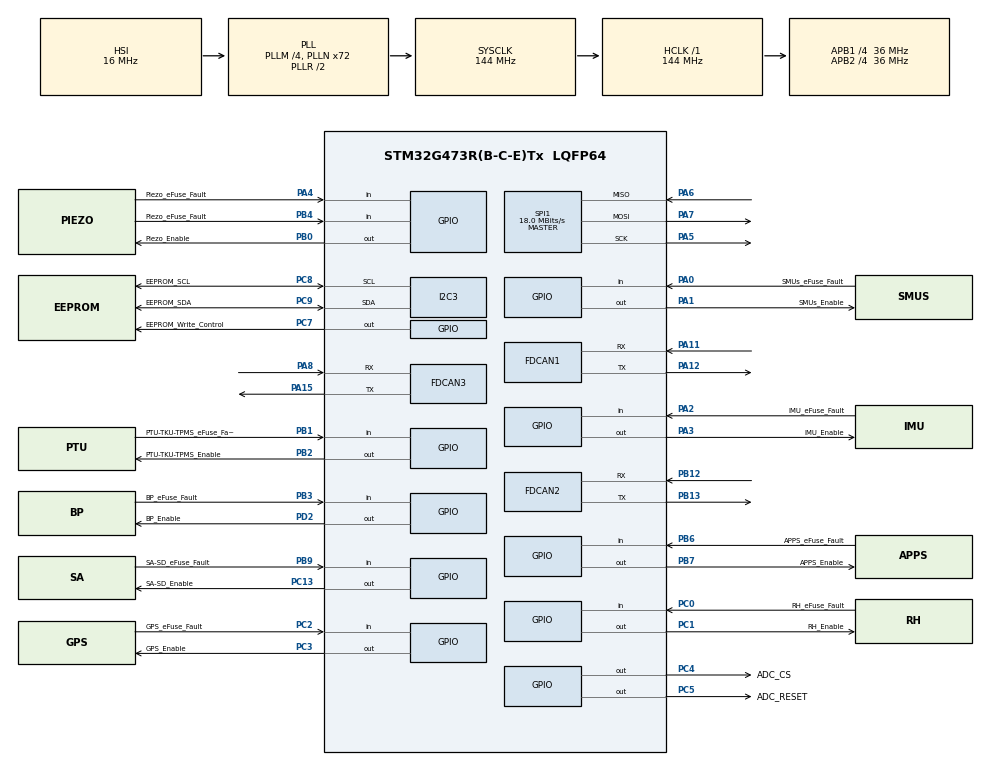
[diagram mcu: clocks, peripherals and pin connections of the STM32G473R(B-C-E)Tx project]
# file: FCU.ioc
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Dma.Request0=SPI1_RX
Dma.Request1=SPI1_TX
Dma.SPI1_RX.0.Direction=DMA_PERIPH_TO_MEMORY
Dma.SPI1_RX.0.EventEnable=DISABLE
Dma.SPI1_RX.0.Instance=DMA1_Channel1
Dma.SPI1_RX.0.MemDataAlignment=DMA_MDATAALIGN_BYTE
Dma.SPI1_RX.0.MemInc=DMA_MINC_ENABLE
Dma.SPI1_RX.0.Mode=DMA_NORMAL
Dma.SPI1_RX.0.PeriphDataAlignment=DMA_PDATAALIGN_BYTE
Dma.SPI1_RX.0.PeriphInc=DMA_PINC_DISABLE
Dma.SPI1_RX.0.Polarity=HAL_DMAMUX_REQ_GEN_RISING
Dma.SPI1_RX.0.Priority=DMA_PRIORITY_LOW
Dma.SPI1_RX.0.RequestNumber=1
Dma.SPI1_RX.0.SignalID=NONE
Dma.SPI1_RX.0.SyncEnable=DISABLE
Dma.SPI1_RX.0.SyncPolarity=HAL_DMAMUX_SYNC_NO_EVENT
Dma.SPI1_RX.0.SyncRequestNumber=1
Dma.SPI1_RX.0.SyncSignalID=NONE
Dma.SPI1_TX.1.Direction=DMA_MEMORY_TO_PERIPH
Dma.SPI1_TX.1.EventEnable=DISABLE
Dma.SPI1_TX.1.Instance=DMA1_Channel2
Dma.SPI1_TX.1.MemDataAlignment=DMA_MDATAALIGN_BYTE
Dma.SPI1_TX.1.MemInc=DMA_MINC_ENABLE
Dma.SPI1_TX.1.Mode=DMA_NORMAL
Dma.SPI1_TX.1.PeriphDataAlignment=DMA_PDATAALIGN_BYTE
Dma.SPI1_TX.1.PeriphInc=DMA_PINC_DISABLE
Dma.SPI1_TX.1.Polarity=HAL_DMAMUX_REQ_GEN_RISING
Dma.SPI1_TX.1.Priority=DMA_PRIORITY_LOW
Dma.SPI1_TX.1.RequestNumber=1
Dma.SPI1_TX.1.SignalID=NONE
Dma.SPI1_TX.1.SyncEnable=DISABLE
Dma.SPI1_TX.1.SyncPolarity=HAL_DMAMUX_SYNC_NO_EVENT
Dma.SPI1_TX.1.SyncRequestNumber=1
Dma.SPI1_TX.1.SyncSignalID=NONE
FDCAN1.CalculateBaudRateNominal=999999
FDCAN1.CalculateTimeBitNominal=1000
FDCAN1.CalculateTimeQuantumNominal=83.33333333333334
FDCAN1.FrameFormat=FDCAN_FRAME_FD_NO_BRS
FDCAN1.NominalPrescaler=3
FDCAN1.NominalTimeSeg1=8
FDCAN1.NominalTimeSeg2=3
FDCAN1.StdFiltersNbr=28
FDCAN2.CalculateBaudRateNominal=999999
FDCAN2.CalculateTimeBitNominal=1000
FDCAN2.CalculateTimeQuantumNominal=83.33333333333334
FDCAN2.NominalPrescaler=3
FDCAN2.NominalTimeSeg1=8
FDCAN2.NominalTimeSeg2=3
FDCAN2.StdFiltersNbr=28
FDCAN3.CalculateBaudRateNominal=999999
FDCAN3.CalculateTimeBitNominal=1000
FDCAN3.CalculateTimeQuantumNominal=83.33333333333334
FDCAN3.NominalPrescaler=3
FDCAN3.NominalTimeSeg1=8
FDCAN3.NominalTimeSeg2=3
FDCAN3.StdFiltersNbr=28
I2C3.Timing=0x00808CD2
Mcu.Family=STM32G4
Mcu.Name=STM32G473R(B-C-E)Tx
Mcu.Package=LQFP64
NVIC.DMA1_Channel1_IRQn=true\:6\:0\:true\:false\:true\:false\:true\:true
NVIC.DMA1_Channel2_IRQn=true\:6\:0\:true\:false\:true\:false\:true\:true
NVIC.PriorityGroup=NVIC_PRIORITYGROUP_4
PA0.GPIO_Label=SMUs_eFuse_Fault
PA0.Signal=GPIO_Input
PA1.GPIO_Label=SMUs_Enable
PA1.GPIO_ModeDefaultOutputPP=GPIO_MODE_OUTPUT_OD
PA1.GPIO_PuPd=GPIO_NOPULL
PA1.Signal=GPIO_Output
PA11.GPIO_Speed=GPIO_SPEED_FREQ_LOW
PA11.Mode=FDCAN_Activate
PA11.Signal=FDCAN1_RX
PA12.GPIO_PuPd=GPIO_NOPULL
PA12.Mode=FDCAN_Activate
PA12.Signal=FDCAN1_TX
PA13.Mode=Serial_Wire
PA13.Signal=SYS_JTMS-SWDIO
PA14.Mode=Serial_Wire
PA14.Signal=SYS_JTCK-SWCLK
PA15.Mode=FDCAN_Activate
PA15.Signal=FDCAN3_TX
PA2.GPIO_Label=IMU_eFuse_Fault
PA2.Signal=GPIO_Input
PA3.GPIO_Label=IMU_Enable
PA3.GPIO_ModeDefaultOutputPP=GPIO_MODE_OUTPUT_OD
PA3.GPIO_PuPd=GPIO_NOPULL
PA3.Signal=GPIO_Output
PA4.GPIO_Label=Piezo_eFuse_Fault
PA4.Signal=GPIO_Input
PA5.Mode=Full_Duplex_Master
PA5.Signal=SPI1_SCK
PA6.Mode=Full_Duplex_Master
PA6.Signal=SPI1_MISO
PA7.Mode=Full_Duplex_Master
PA7.Signal=SPI1_MOSI
PA8.Mode=FDCAN_Activate
PA8.Signal=FDCAN3_RX
PB0.GPIO_Label=Piezo_Enable
PB0.GPIO_ModeDefaultOutputPP=GPIO_MODE_OUTPUT_OD
PB0.GPIO_PuPd=GPIO_NOPULL
PB0.Signal=GPIO_Output
PB1.GPIO_Label=PTU-TKU-TPMS_eFuse_Fault
PB1.Signal=GPIO_Input
PB12.Mode=FDCAN_Activate
PB12.Signal=FDCAN2_RX
PB13.Mode=FDCAN_Activate
PB13.Signal=FDCAN2_TX
PB2.GPIO_Label=PTU-TKU-TPMS_Enable
PB2.GPIO_ModeDefaultOutputPP=GPIO_MODE_OUTPUT_OD
PB2.GPIO_PuPd=GPIO_NOPULL
PB2.PinState=GPIO_PIN_SET
PB2.Signal=GPIO_Output
PB3.GPIO_Label=BP_eFuse_Fault
PB3.Signal=GPIO_Input
PB4.GPIO_Label=Piezo_eFuse_Fault
PB4.Signal=GPIO_Input
PB6.GPIO_Label=APPS_eFuse_Fault
PB6.Signal=GPIO_Input
PB7.GPIO_Label=APPS_Enable
PB7.GPIO_ModeDefaultOutputPP=GPIO_MODE_OUTPUT_OD
PB7.GPIO_PuPd=GPIO_NOPULL
PB7.PinState=GPIO_PIN_SET
PB7.Signal=GPIO_Output
PB9.GPIO_Label=SA-SD_eFuse_Fault
PB9.Signal=GPIO_Input
PC0.GPIO_Label=RH_eFuse_Fault
PC0.Signal=GPIO_Input
PC1.GPIO_Label=RH_Enable
PC1.GPIO_ModeDefaultOutputPP=GPIO_MODE_OUTPUT_OD
PC1.GPIO_PuPd=GPIO_NOPULL
PC1.Signal=GPIO_Output
PC13.GPIO_Label=SA-SD_Enable
PC13.GPIO_ModeDefaultOutputPP=GPIO_MODE_OUTPUT_OD
PC13.GPIO_PuPd=GPIO_NOPULL
PC13.Signal=GPIO_Output
PC2.GPIO_Label=GPS_eFuse_Fault
PC2.Signal=GPIO_Input
PC3.GPIO_Label=GPS_Enable
PC3.GPIO_ModeDefaultOutputPP=GPIO_MODE_OUTPUT_OD
PC3.GPIO_PuPd=GPIO_NOPULL
PC3.Signal=GPIO_Output
PC4.GPIO_Label=ADC_CS
PC4.PinState=GPIO_PIN_SET
PC4.Signal=GPIO_Output
PC5.GPIO_Label=ADC_RESET
PC5.PinState=GPIO_PIN_SET
PC5.Signal=GPIO_Output
PC7.GPIO_Label=EEPROM_Write_Control
PC7.Signal=GPIO_Output
PC8.GPIO_Label=EEPROM_SCL
PC8.Mode=I2C
PC8.Signal=I2C3_SCL
PC9.GPIO_Label=EEPROM_SDA
PC9.Mode=I2C
PC9.Signal=I2C3_SDA
PD2.GPIO_Label=BP_Enable
PD2.Signal=GPIO_Output
ProjectManager.HeapSize=0x200
ProjectManager.StackSize=0x400
ProjectManager.TargetToolchain=MDK-ARM V5.32
RCC.ADC12Freq_Value=144000000
RCC.ADC345Freq_Value=144000000
RCC.AHBFreq_Value=144000000
RCC.APB1CLKDivider=RCC_HCLK_DIV4
RCC.APB1Freq_Value=36000000
RCC.APB1TimFreq_Value=72000000
RCC.APB2CLKDivider=RCC_HCLK_DIV4
RCC.APB2Freq_Value=36000000
RCC.APB2TimFreq_Value=72000000
RCC.CortexFreq_Value=144000000
RCC.EXTERNAL_CLOCK_VALUE=12288000
RCC.HCLKFreq_Value=144000000
RCC.HSE_VALUE=8000000
RCC.HSI48_VALUE=48000000
RCC.HSI_VALUE=16000000
RCC.LSE_VALUE=32768
RCC.PLLM=RCC_PLLM_DIV4
RCC.PLLN=72
RCC.SYSCLKFreq_VALUE=144000000
RCC.SYSCLKSource=RCC_SYSCLKSOURCE_PLLCLK
RCC.USBFreq_Value=144000000
RCC.VCOOutputFreq_Value=288000000
SPI1.BaudRatePrescaler=SPI_BAUDRATEPRESCALER_2
SPI1.CalculateBaudRate=18.0 MBits/s
SPI1.DataSize=SPI_DATASIZE_8BIT
SPI1.Direction=SPI_DIRECTION_2LINES
SPI1.Mode=SPI_MODE_MASTER
SPI1.VirtualType=VM_MASTER
VP_SYS_VS_DBSignals.Mode=DisableDeadBatterySignals
board=custom

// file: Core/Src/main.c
/* USER CODE BEGIN Header */
/**
  ******************************************************************************
  * @file           : main.c
  * @brief          : Main program body
  ******************************************************************************
  * @attention
  *
  * Copyright (c) 2024 STMicroelectronics.
  * All rights reserved.
  *
  * This software is licensed under terms that can be found in the LICENSE file
  * in the root directory of this software component.
  * If no LICENSE file comes with this software, it is provided AS-IS.
  *
  ******************************************************************************
  */
/* USER CODE END Header */
#include "main.h"

/* USER CODE BEGIN PM */
#define main initHAL
/* USER CODE END PM */

FDCAN_HandleTypeDef hfdcan1;
FDCAN_HandleTypeDef hfdcan2;
FDCAN_HandleTypeDef hfdcan3;

I2C_HandleTypeDef hi2c3;

SPI_HandleTypeDef hspi1;
DMA_HandleTypeDef hdma_spi1_rx;
DMA_HandleTypeDef hdma_spi1_tx;

void SystemClock_Config(void);
static void MX_GPIO_Init(void);
static void MX_DMA_Init(void);
static void MX_I2C3_Init(void);
static void MX_SPI1_Init(void);
static void MX_FDCAN2_Init(void);
static void MX_FDCAN1_Init(void);
static void MX_FDCAN3_Init(void);

int main(void)
{

  /* MCU Configuration--------------------------------------------------------*/

  /* Reset of all peripherals, Initializes the Flash interface and the Systick. */
  HAL_Init();

  /* Configure the system clock */
  SystemClock_Config();

  /* Initialize all configured peripherals */
  MX_GPIO_Init();
  MX_DMA_Init();
  MX_I2C3_Init();
  MX_SPI1_Init();
  MX_FDCAN2_Init();
  MX_FDCAN1_Init();
  MX_FDCAN3_Init();

  /* Infinite loop */
  while (1)
  {

    /* USER CODE BEGIN 3 */
    break;
  }
  /* USER CODE END 3 */
}

void SystemClock_Config(void)
{
  RCC_OscInitTypeDef RCC_OscInitStruct = {0};
  RCC_ClkInitTypeDef RCC_ClkInitStruct = {0};

  /** Configure the main internal regulator output voltage
  */
  HAL_PWREx_ControlVoltageScaling(PWR_REGULATOR_VOLTAGE_SCALE1);

  /** Initializes the RCC Oscillators according to the specified parameters
  * in the RCC_OscInitTypeDef structure.
  */
  RCC_OscInitStruct.OscillatorType = RCC_OSCILLATORTYPE_HSI;
  RCC_OscInitStruct.HSIState = RCC_HSI_ON;
  RCC_OscInitStruct.HSICalibrationValue = RCC_HSICALIBRATION_DEFAULT;
  RCC_OscInitStruct.PLL.PLLState = RCC_PLL_ON;
  RCC_OscInitStruct.PLL.PLLSource = RCC_PLLSOURCE_HSI;
  RCC_OscInitStruct.PLL.PLLM = RCC_PLLM_DIV4;
  RCC_OscInitStruct.PLL.PLLN = 72;
  RCC_OscInitStruct.PLL.PLLP = RCC_PLLP_DIV2;
  RCC_OscInitStruct.PLL.PLLQ = RCC_PLLQ_DIV2;
  RCC_OscInitStruct.PLL.PLLR = RCC_PLLR_DIV2;
  if (HAL_RCC_OscConfig(&RCC_OscInitStruct) != HAL_OK)
  {
    Error_Handler();
  }

  /** Initializes the CPU, AHB and APB buses clocks
  */
  RCC_ClkInitStruct.ClockType = RCC_CLOCKTYPE_HCLK|RCC_CLOCKTYPE_SYSCLK
                              |RCC_CLOCKTYPE_PCLK1|RCC_CLOCKTYPE_PCLK2;
  RCC_ClkInitStruct.SYSCLKSource = RCC_SYSCLKSOURCE_PLLCLK;
  RCC_ClkInitStruct.AHBCLKDivider = RCC_SYSCLK_DIV1;
  RCC_ClkInitStruct.APB1CLKDivider = RCC_HCLK_DIV4;
  RCC_ClkInitStruct.APB2CLKDivider = RCC_HCLK_DIV4;

  if (HAL_RCC_ClockConfig(&RCC_ClkInitStruct, FLASH_LATENCY_4) != HAL_OK)
  {
    Error_Handler();
  }
}

static void MX_FDCAN1_Init(void)
{

  hfdcan1.Instance = FDCAN1;
  hfdcan1.Init.ClockDivider = FDCAN_CLOCK_DIV1;
  hfdcan1.Init.FrameFormat = FDCAN_FRAME_FD_NO_BRS;
  hfdcan1.Init.Mode = FDCAN_MODE_NORMAL;
  hfdcan1.Init.AutoRetransmission = DISABLE;
  hfdcan1.Init.TransmitPause = DISABLE;
  hfdcan1.Init.ProtocolException = DISABLE;
  hfdcan1.Init.NominalPrescaler = 3;
  hfdcan1.Init.NominalSyncJumpWidth = 1;
  hfdcan1.Init.NominalTimeSeg1 = 8;
  hfdcan1.Init.NominalTimeSeg2 = 3;
  hfdcan1.Init.DataPrescaler = 1;
  hfdcan1.Init.DataSyncJumpWidth = 1;
  hfdcan1.Init.DataTimeSeg1 = 1;
  hfdcan1.Init.DataTimeSeg2 = 1;
  hfdcan1.Init.StdFiltersNbr = 28;
  hfdcan1.Init.ExtFiltersNbr = 0;
  hfdcan1.Init.TxFifoQueueMode = FDCAN_TX_FIFO_OPERATION;
  if (HAL_FDCAN_Init(&hfdcan1) != HAL_OK)
  {
    Error_Handler();
  }

}

static void MX_FDCAN2_Init(void)
{

  hfdcan2.Instance = FDCAN2;
  hfdcan2.Init.ClockDivider = FDCAN_CLOCK_DIV1;
  hfdcan2.Init.FrameFormat = FDCAN_FRAME_CLASSIC;
  hfdcan2.Init.Mode = FDCAN_MODE_NORMAL;
  hfdcan2.Init.AutoRetransmission = DISABLE;
  hfdcan2.Init.TransmitPause = DISABLE;
  hfdcan2.Init.ProtocolException = DISABLE;
  hfdcan2.Init.NominalPrescaler = 3;
  hfdcan2.Init.NominalSyncJumpWidth = 1;
  hfdcan2.Init.NominalTimeSeg1 = 8;
  hfdcan2.Init.NominalTimeSeg2 = 3;
  hfdcan2.Init.DataPrescaler = 1;
  hfdcan2.Init.DataSyncJumpWidth = 1;
  hfdcan2.Init.DataTimeSeg1 = 1;
  hfdcan2.Init.DataTimeSeg2 = 1;
  hfdcan2.Init.StdFiltersNbr = 28;
  hfdcan2.Init.ExtFiltersNbr = 0;
  hfdcan2.Init.TxFifoQueueMode = FDCAN_TX_FIFO_OPERATION;
  if (HAL_FDCAN_Init(&hfdcan2) != HAL_OK)
  {
    Error_Handler();
  }

}

static void MX_FDCAN3_Init(void)
{

  hfdcan3.Instance = FDCAN3;
  hfdcan3.Init.ClockDivider = FDCAN_CLOCK_DIV1;
  hfdcan3.Init.FrameFormat = FDCAN_FRAME_CLASSIC;
  hfdcan3.Init.Mode = FDCAN_MODE_NORMAL;
  hfdcan3.Init.AutoRetransmission = DISABLE;
  hfdcan3.Init.TransmitPause = DISABLE;
  hfdcan3.Init.ProtocolException = DISABLE;
  hfdcan3.Init.NominalPrescaler = 3;
  hfdcan3.Init.NominalSyncJumpWidth = 1;
  hfdcan3.Init.NominalTimeSeg1 = 8;
  hfdcan3.Init.NominalTimeSeg2 = 3;
  hfdcan3.Init.DataPrescaler = 1;
  hfdcan3.Init.DataSyncJumpWidth = 1;
  hfdcan3.Init.DataTimeSeg1 = 1;
  hfdcan3.Init.DataTimeSeg2 = 1;
  hfdcan3.Init.StdFiltersNbr = 28;
  hfdcan3.Init.ExtFiltersNbr = 0;
  hfdcan3.Init.TxFifoQueueMode = FDCAN_TX_FIFO_OPERATION;
  if (HAL_FDCAN_Init(&hfdcan3) != HAL_OK)
  {
    Error_Handler();
  }

}

static void MX_I2C3_Init(void)
{

  hi2c3.Instance = I2C3;
  hi2c3.Init.Timing = 0x00808CD2;
  hi2c3.Init.OwnAddress1 = 0;
  hi2c3.Init.AddressingMode = I2C_ADDRESSINGMODE_7BIT;
  hi2c3.Init.DualAddressMode = I2C_DUALADDRESS_DISABLE;
  hi2c3.Init.OwnAddress2 = 0;
  hi2c3.Init.OwnAddress2Masks = I2C_OA2_NOMASK;
  hi2c3.Init.GeneralCallMode = I2C_GENERALCALL_DISABLE;
  hi2c3.Init.NoStretchMode = I2C_NOSTRETCH_DISABLE;
  if (HAL_I2C_Init(&hi2c3) != HAL_OK)
  {
    Error_Handler();
  }

  /** Configure Analogue filter
  */
  if (HAL_I2CEx_ConfigAnalogFilter(&hi2c3, I2C_ANALOGFILTER_ENABLE) != HAL_OK)
  {
    Error_Handler();
  }

  /** Configure Digital filter
  */
  if (HAL_I2CEx_ConfigDigitalFilter(&hi2c3, 0) != HAL_OK)
  {
    Error_Handler();
  }

}

static void MX_SPI1_Init(void)
{

  /* SPI1 parameter configuration*/
  hspi1.Instance = SPI1;
  hspi1.Init.Mode = SPI_MODE_MASTER;
  hspi1.Init.Direction = SPI_DIRECTION_2LINES;
  hspi1.Init.DataSize = SPI_DATASIZE_8BIT;
  hspi1.Init.CLKPolarity = SPI_POLARITY_LOW;
  hspi1.Init.CLKPhase = SPI_PHASE_1EDGE;
  hspi1.Init.NSS = SPI_NSS_SOFT;
  hspi1.Init.BaudRatePrescaler = SPI_BAUDRATEPRESCALER_2;
  hspi1.Init.FirstBit = SPI_FIRSTBIT_MSB;
  hspi1.Init.TIMode = SPI_TIMODE_DISABLE;
  hspi1.Init.CRCCalculation = SPI_CRCCALCULATION_DISABLE;
  hspi1.Init.CRCPolynomial = 7;
  hspi1.Init.CRCLength = SPI_CRC_LENGTH_DATASIZE;
  hspi1.Init.NSSPMode = SPI_NSS_PULSE_ENABLE;
  if (HAL_SPI_Init(&hspi1) != HAL_OK)
  {
    Error_Handler();
  }

}

static void MX_DMA_Init(void)
{

  /* DMA controller clock enable */
  __HAL_RCC_DMAMUX1_CLK_ENABLE();
  __HAL_RCC_DMA1_CLK_ENABLE();

  /* DMA interrupt init */
  /* DMA1_Channel1_IRQn interrupt configuration */
  HAL_NVIC_SetPriority(DMA1_Channel1_IRQn, 6, 0);
  HAL_NVIC_EnableIRQ(DMA1_Channel1_IRQn);
  /* DMA1_Channel2_IRQn interrupt configuration */
  HAL_NVIC_SetPriority(DMA1_Channel2_IRQn, 6, 0);
  HAL_NVIC_EnableIRQ(DMA1_Channel2_IRQn);

}

static void MX_GPIO_Init(void)
{
  GPIO_InitTypeDef GPIO_InitStruct = {0};

  /* GPIO Ports Clock Enable */
  __HAL_RCC_GPIOC_CLK_ENABLE();
  __HAL_RCC_GPIOA_CLK_ENABLE();
  __HAL_RCC_GPIOB_CLK_ENABLE();
  __HAL_RCC_GPIOD_CLK_ENABLE();

  /*Configure GPIO pin Output Level */
  HAL_GPIO_WritePin(GPIOC, SA_SD_Enable_Pin|RH_Enable_Pin|GPS_Enable_Pin|EEPROM_Write_Control_Pin, GPIO_PIN_RESET);

  /*Configure GPIO pin Output Level */
  HAL_GPIO_WritePin(GPIOA, SMUs_Enable_Pin|IMU_Enable_Pin, GPIO_PIN_RESET);

  /*Configure GPIO pin Output Level */
  HAL_GPIO_WritePin(GPIOC, ADC_CS_Pin|ADC_RESET_Pin, GPIO_PIN_SET);

  /*Configure GPIO pin Output Level */
  HAL_GPIO_WritePin(Piezo_Enable_GPIO_Port, Piezo_Enable_Pin, GPIO_PIN_RESET);

  /*Configure GPIO pin Output Level */
  HAL_GPIO_WritePin(GPIOB, PTU_TKU_TPMS_Enable_Pin|APPS_Enable_Pin, GPIO_PIN_SET);

  /*Configure GPIO pin Output Level */
  HAL_GPIO_WritePin(BP_Enable_GPIO_Port, BP_Enable_Pin, GPIO_PIN_RESET);

  /*Configure GPIO pins : SA_SD_Enable_Pin RH_Enable_Pin GPS_Enable_Pin */
  GPIO_InitStruct.Pin = SA_SD_Enable_Pin|RH_Enable_Pin|GPS_Enable_Pin;
  GPIO_InitStruct.Mode = GPIO_MODE_OUTPUT_OD;
  GPIO_InitStruct.Pull = GPIO_NOPULL;
  GPIO_InitStruct.Speed = GPIO_SPEED_FREQ_LOW;
  HAL_GPIO_Init(GPIOC, &GPIO_InitStruct);

  /*Configure GPIO pins : RH_eFuse_Fault_Pin GPS_eFuse_Fault_Pin */
  GPIO_InitStruct.Pin = RH_eFuse_Fault_Pin|GPS_eFuse_Fault_Pin;
  GPIO_InitStruct.Mode = GPIO_MODE_INPUT;
  GPIO_InitStruct.Pull = GPIO_NOPULL;
  HAL_GPIO_Init(GPIOC, &GPIO_InitStruct);

  /*Configure GPIO pins : SMUs_eFuse_Fault_Pin IMU_eFuse_Fault_Pin Piezo_eFuse_Fault_Pin */
  GPIO_InitStruct.Pin = SMUs_eFuse_Fault_Pin|IMU_eFuse_Fault_Pin|Piezo_eFuse_Fault_Pin;
  GPIO_InitStruct.Mode = GPIO_MODE_INPUT;
  GPIO_InitStruct.Pull = GPIO_NOPULL;
  HAL_GPIO_Init(GPIOA, &GPIO_InitStruct);

  /*Configure GPIO pins : SMUs_Enable_Pin IMU_Enable_Pin */
  GPIO_InitStruct.Pin = SMUs_Enable_Pin|IMU_Enable_Pin;
  GPIO_InitStruct.Mode = GPIO_MODE_OUTPUT_OD;
  GPIO_InitStruct.Pull = GPIO_NOPULL;
  GPIO_InitStruct.Speed = GPIO_SPEED_FREQ_LOW;
  HAL_GPIO_Init(GPIOA, &GPIO_InitStruct);

  /*Configure GPIO pins : ADC_CS_Pin ADC_RESET_Pin EEPROM_Write_Control_Pin */
  GPIO_InitStruct.Pin = ADC_CS_Pin|ADC_RESET_Pin|EEPROM_Write_Control_Pin;
  GPIO_InitStruct.Mode = GPIO_MODE_OUTPUT_PP;
  GPIO_InitStruct.Pull = GPIO_NOPULL;
  GPIO_InitStruct.Speed = GPIO_SPEED_FREQ_LOW;
  HAL_GPIO_Init(GPIOC, &GPIO_InitStruct);

  /*Configure GPIO pins : Piezo_Enable_Pin PTU_TKU_TPMS_Enable_Pin APPS_Enable_Pin */
  GPIO_InitStruct.Pin = Piezo_Enable_Pin|PTU_TKU_TPMS_Enable_Pin|APPS_Enable_Pin;
  GPIO_InitStruct.Mode = GPIO_MODE_OUTPUT_OD;
  GPIO_InitStruct.Pull = GPIO_NOPULL;
  GPIO_InitStruct.Speed = GPIO_SPEED_FREQ_LOW;
  HAL_GPIO_Init(GPIOB, &GPIO_InitStruct);

  /*Configure GPIO pins : PTU_TKU_TPMS_eFuse_Fault_Pin BP_eFuse_Fault_Pin Piezo_eFuse_FaultB4_Pin APPS_eFuse_Fault_Pin
                           SA_SD_eFuse_Fault_Pin */
  GPIO_InitStruct.Pin = PTU_TKU_TPMS_eFuse_Fault_Pin|BP_eFuse_Fault_Pin|Piezo_eFuse_FaultB4_Pin|APPS_eFuse_Fault_Pin
                          |SA_SD_eFuse_Fault_Pin;
  GPIO_InitStruct.Mode = GPIO_MODE_INPUT;
  GPIO_InitStruct.Pull = GPIO_NOPULL;
  HAL_GPIO_Init(GPIOB, &GPIO_InitStruct);

  /*Configure GPIO pin : BP_Enable_Pin */
  GPIO_InitStruct.Pin = BP_Enable_Pin;
  GPIO_InitStruct.Mode = GPIO_MODE_OUTPUT_PP;
  GPIO_InitStruct.Pull = GPIO_NOPULL;
  GPIO_InitStruct.Speed = GPIO_SPEED_FREQ_LOW;
  HAL_GPIO_Init(BP_Enable_GPIO_Port, &GPIO_InitStruct);

}

void Error_Handler(void)
{
  __disable_irq();
  while (1)
  {
  }
}
